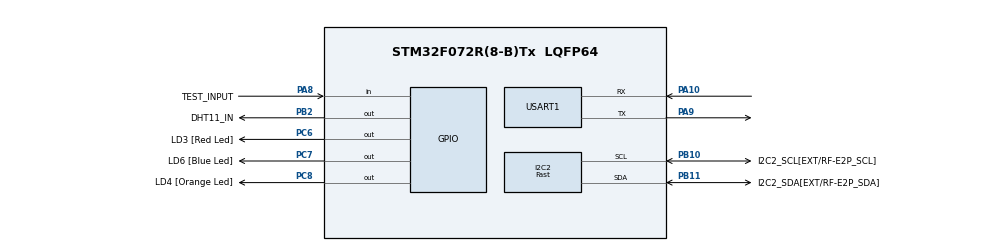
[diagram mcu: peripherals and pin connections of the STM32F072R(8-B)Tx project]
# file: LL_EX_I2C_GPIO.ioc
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I2C2.I2C_Speed_Mode=I2C_Fast
I2C2.Timing=0x2010091A
Mcu.Family=STM32F0
Mcu.Name=STM32F072R(8-B)Tx
Mcu.Package=LQFP64
NVIC.USART1_IRQn=true\:0\:0\:false\:false\:true\:true\:true
PA10.Mode=Asynchronous
PA10.Signal=USART1_RX
PA13.GPIO_Label=SWDIO
PA13.Mode=Serial_Wire
PA13.Signal=SYS_SWDIO
PA14.GPIO_Label=SWCLK
PA14.Mode=Serial_Wire
PA14.Signal=SYS_SWCLK
PA8.GPIO_Label=TEST_INPUT
PA8.Signal=GPIO_Input
PA9.Mode=Asynchronous
PA9.Signal=USART1_TX
PB10.GPIO_Label=I2C2_SCL[EXT/RF-E2P_SCL]
PB10.GPIO_Pu=GPIO_PULLUP
PB10.Mode=I2C
PB10.Signal=I2C2_SCL
PB11.GPIO_Label=I2C2_SDA[EXT/RF-E2P_SDA]
PB11.GPIO_Pu=GPIO_PULLUP
PB11.Mode=I2C
PB11.Signal=I2C2_SDA
PB2.GPIO_Label=DHT11_IN
PB2.GPIO_PuPd=GPIO_PULLUP
PB2.GPIO_Speed=GPIO_SPEED_FREQ_LOW
PB2.Signal=GPIO_Output
PC6.GPIO_Label=LD3 [Red Led]
PC6.Signal=GPIO_Output
PC7.GPIO_Label=LD6 [Blue Led]
PC7.Signal=GPIO_Output
PC8.GPIO_Label=LD4 [Orange Led]
PC8.Signal=GPIO_Output
ProjectManager.HeapSize=0x200
ProjectManager.StackSize=0x400
ProjectManager.TargetToolchain=STM32CubeIDE
RCC.AHBFreq_Value=48000000
RCC.APB1Freq_Value=48000000
RCC.APB1TimFreq_Value=48000000
RCC.HCLKFreq_Value=48000000
RCC.PLLMUL=RCC_PLL_MUL6
RCC.SYSCLKFreq_VALUE=48000000
RCC.SYSCLKSource=RCC_SYSCLKSOURCE_PLLCLK
TIM6.Prescaler=47
USART1.VirtualMode-Asynchronous=VM_ASYNC
VP_TIM6_VS_ClockSourceINT.Mode=Enable_Timer
board=STM32F072B-DISCO

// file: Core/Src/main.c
/* USER CODE BEGIN Header */
/**
  ******************************************************************************
  * @file           : main.c
  * @brief          : Main program body
  ******************************************************************************
  * @attention
  *
  * <h2><center>&copy; Copyright (c) 2021 STMicroelectronics.
  * All rights reserved.</center></h2>
  *
  * This software component is licensed by ST under BSD 3-Clause license,
  * the "License"; You may not use this file except in compliance with the
  * License. You may obtain a copy of the License at:
  *                        opensource.org/licenses/BSD-3-Clause
  *
  ******************************************************************************
  */
/* USER CODE END Header */
#include "main.h"

/* USER CODE BEGIN Includes */
#include "BSL.h"
/* USER CODE END Includes */

void SystemClock_Config(void);
static void MX_GPIO_Init(void);
static void MX_TIM6_Init(void);
static void MX_USART1_UART_Init(void);

int main(void)
{

  /* MCU Configuration--------------------------------------------------------*/

  /* Reset of all peripherals, Initializes the Flash interface and the Systick. */

  LL_APB1_GRP2_EnableClock(LL_APB1_GRP2_PERIPH_SYSCFG);
  LL_APB1_GRP1_EnableClock(LL_APB1_GRP1_PERIPH_PWR);

  /* System interrupt init*/

  /* Configure the system clock */
  SystemClock_Config();

  /* Initialize all configured peripherals */
  MX_GPIO_Init();
  MX_I2C2_Init();
  MX_TIM6_Init();
  MX_USART1_UART_Init();
  /* USER CODE BEGIN 2 */
  BSL_Startup();

  BSL_Config();

  BSL_Control();
  /* USER CODE END 2 */

  /* Infinite loop */
  while (1)
  {

  }
}

void SystemClock_Config(void)
{
  LL_FLASH_SetLatency(LL_FLASH_LATENCY_1);
  while(LL_FLASH_GetLatency() != LL_FLASH_LATENCY_1)
  {
  }
  LL_RCC_HSI_Enable();

   /* Wait till HSI is ready */
  while(LL_RCC_HSI_IsReady() != 1)
  {

  }
  LL_RCC_HSI_SetCalibTrimming(16);
  LL_RCC_PLL_ConfigDomain_SYS(LL_RCC_PLLSOURCE_HSI, LL_RCC_PLL_MUL_6, LL_RCC_PREDIV_DIV_1);
  LL_RCC_PLL_Enable();

   /* Wait till PLL is ready */
  while(LL_RCC_PLL_IsReady() != 1)
  {

  }
  LL_RCC_SetAHBPrescaler(LL_RCC_SYSCLK_DIV_1);
  LL_RCC_SetAPB1Prescaler(LL_RCC_APB1_DIV_1);
  LL_RCC_SetSysClkSource(LL_RCC_SYS_CLKSOURCE_PLL);

   /* Wait till System clock is ready */
  while(LL_RCC_GetSysClkSource() != LL_RCC_SYS_CLKSOURCE_STATUS_PLL)
  {

  }
  LL_Init1msTick(48000000);
  LL_SetSystemCoreClock(48000000);
  LL_RCC_SetUSARTClockSource(LL_RCC_USART1_CLKSOURCE_PCLK1);
}

void MX_I2C2_Init(void)
{

  LL_I2C_InitTypeDef I2C_InitStruct = {0};

  LL_GPIO_InitTypeDef GPIO_InitStruct = {0};

  LL_AHB1_GRP1_EnableClock(LL_AHB1_GRP1_PERIPH_GPIOB);
  /**I2C2 GPIO Configuration
  PB10   ------> I2C2_SCL
  PB11   ------> I2C2_SDA
  */
  GPIO_InitStruct.Pin = I2C2_SCL_Pin;
  GPIO_InitStruct.Mode = LL_GPIO_MODE_ALTERNATE;
  GPIO_InitStruct.Speed = LL_GPIO_SPEED_FREQ_HIGH;
  GPIO_InitStruct.OutputType = LL_GPIO_OUTPUT_OPENDRAIN;
  GPIO_InitStruct.Pull = LL_GPIO_PULL_UP;
  GPIO_InitStruct.Alternate = LL_GPIO_AF_1;
  LL_GPIO_Init(I2C2_SCL_GPIO_Port, &GPIO_InitStruct);

  GPIO_InitStruct.Pin = I2C2_SDA_Pin;
  GPIO_InitStruct.Mode = LL_GPIO_MODE_ALTERNATE;
  GPIO_InitStruct.Speed = LL_GPIO_SPEED_FREQ_HIGH;
  GPIO_InitStruct.OutputType = LL_GPIO_OUTPUT_OPENDRAIN;
  GPIO_InitStruct.Pull = LL_GPIO_PULL_UP;
  GPIO_InitStruct.Alternate = LL_GPIO_AF_1;
  LL_GPIO_Init(I2C2_SDA_GPIO_Port, &GPIO_InitStruct);

  /* Peripheral clock enable */
  LL_APB1_GRP1_EnableClock(LL_APB1_GRP1_PERIPH_I2C2);

  /** I2C Initialization
  */
  LL_I2C_DisableOwnAddress2(I2C2);
  LL_I2C_DisableGeneralCall(I2C2);
  LL_I2C_EnableClockStretching(I2C2);
  I2C_InitStruct.PeripheralMode = LL_I2C_MODE_I2C;
  I2C_InitStruct.Timing = 0x2010091A;
  I2C_InitStruct.AnalogFilter = LL_I2C_ANALOGFILTER_ENABLE;
  I2C_InitStruct.DigitalFilter = 0;
  I2C_InitStruct.OwnAddress1 = 0;
  I2C_InitStruct.TypeAcknowledge = LL_I2C_ACK;
  I2C_InitStruct.OwnAddrSize = LL_I2C_OWNADDRESS1_7BIT;
  LL_I2C_Init(I2C2, &I2C_InitStruct);
  LL_I2C_EnableAutoEndMode(I2C2);
  LL_I2C_SetOwnAddress2(I2C2, 0, LL_I2C_OWNADDRESS2_NOMASK);

}

static void MX_TIM6_Init(void)
{

  LL_TIM_InitTypeDef TIM_InitStruct = {0};

  /* Peripheral clock enable */
  LL_APB1_GRP1_EnableClock(LL_APB1_GRP1_PERIPH_TIM6);

  TIM_InitStruct.Prescaler = 47;
  TIM_InitStruct.CounterMode = LL_TIM_COUNTERMODE_UP;
  TIM_InitStruct.Autoreload = 65535;
  LL_TIM_Init(TIM6, &TIM_InitStruct);
  LL_TIM_DisableARRPreload(TIM6);
  LL_TIM_SetTriggerOutput(TIM6, LL_TIM_TRGO_RESET);
  LL_TIM_DisableMasterSlaveMode(TIM6);

}

static void MX_USART1_UART_Init(void)
{

  LL_USART_InitTypeDef USART_InitStruct = {0};

  LL_GPIO_InitTypeDef GPIO_InitStruct = {0};

  /* Peripheral clock enable */
  LL_APB1_GRP2_EnableClock(LL_APB1_GRP2_PERIPH_USART1);

  LL_AHB1_GRP1_EnableClock(LL_AHB1_GRP1_PERIPH_GPIOA);
  /**USART1 GPIO Configuration
  PA9   ------> USART1_TX
  PA10   ------> USART1_RX
  */
  GPIO_InitStruct.Pin = LL_GPIO_PIN_9;
  GPIO_InitStruct.Mode = LL_GPIO_MODE_ALTERNATE;
  GPIO_InitStruct.Speed = LL_GPIO_SPEED_FREQ_HIGH;
  GPIO_InitStruct.OutputType = LL_GPIO_OUTPUT_PUSHPULL;
  GPIO_InitStruct.Pull = LL_GPIO_PULL_NO;
  GPIO_InitStruct.Alternate = LL_GPIO_AF_1;
  LL_GPIO_Init(GPIOA, &GPIO_InitStruct);

  GPIO_InitStruct.Pin = LL_GPIO_PIN_10;
  GPIO_InitStruct.Mode = LL_GPIO_MODE_ALTERNATE;
  GPIO_InitStruct.Speed = LL_GPIO_SPEED_FREQ_HIGH;
  GPIO_InitStruct.OutputType = LL_GPIO_OUTPUT_PUSHPULL;
  GPIO_InitStruct.Pull = LL_GPIO_PULL_NO;
  GPIO_InitStruct.Alternate = LL_GPIO_AF_1;
  LL_GPIO_Init(GPIOA, &GPIO_InitStruct);

  /* USART1 interrupt Init */
  NVIC_SetPriority(USART1_IRQn, 0);
  NVIC_EnableIRQ(USART1_IRQn);

  USART_InitStruct.BaudRate = 38400;
  USART_InitStruct.DataWidth = LL_USART_DATAWIDTH_8B;
  USART_InitStruct.StopBits = LL_USART_STOPBITS_1;
  USART_InitStruct.Parity = LL_USART_PARITY_NONE;
  USART_InitStruct.TransferDirection = LL_USART_DIRECTION_TX_RX;
  USART_InitStruct.HardwareFlowControl = LL_USART_HWCONTROL_NONE;
  USART_InitStruct.OverSampling = LL_USART_OVERSAMPLING_16;
  LL_USART_Init(USART1, &USART_InitStruct);
  LL_USART_DisableIT_CTS(USART1);
  LL_USART_ConfigAsyncMode(USART1);
  LL_USART_Enable(USART1);

}

static void MX_GPIO_Init(void)
{
  LL_GPIO_InitTypeDef GPIO_InitStruct = {0};

  /* GPIO Ports Clock Enable */
  LL_AHB1_GRP1_EnableClock(LL_AHB1_GRP1_PERIPH_GPIOB);
  LL_AHB1_GRP1_EnableClock(LL_AHB1_GRP1_PERIPH_GPIOC);
  LL_AHB1_GRP1_EnableClock(LL_AHB1_GRP1_PERIPH_GPIOA);

  /**/
  LL_GPIO_ResetOutputPin(DHT11_IN_GPIO_Port, DHT11_IN_Pin);

  /**/
  LL_GPIO_ResetOutputPin(LD3_GPIO_Port, LD3_Pin);

  /**/
  LL_GPIO_ResetOutputPin(LD6_GPIO_Port, LD6_Pin);

  /**/
  LL_GPIO_ResetOutputPin(LD4_GPIO_Port, LD4_Pin);

  /**/
  GPIO_InitStruct.Pin = DHT11_IN_Pin;
  GPIO_InitStruct.Mode = LL_GPIO_MODE_OUTPUT;
  GPIO_InitStruct.Speed = LL_GPIO_SPEED_FREQ_LOW;
  GPIO_InitStruct.OutputType = LL_GPIO_OUTPUT_PUSHPULL;
  GPIO_InitStruct.Pull = LL_GPIO_PULL_UP;
  LL_GPIO_Init(DHT11_IN_GPIO_Port, &GPIO_InitStruct);

  /**/
  GPIO_InitStruct.Pin = LD3_Pin;
  GPIO_InitStruct.Mode = LL_GPIO_MODE_OUTPUT;
  GPIO_InitStruct.Speed = LL_GPIO_SPEED_FREQ_LOW;
  GPIO_InitStruct.OutputType = LL_GPIO_OUTPUT_PUSHPULL;
  GPIO_InitStruct.Pull = LL_GPIO_PULL_NO;
  LL_GPIO_Init(LD3_GPIO_Port, &GPIO_InitStruct);

  /**/
  GPIO_InitStruct.Pin = LD6_Pin;
  GPIO_InitStruct.Mode = LL_GPIO_MODE_OUTPUT;
  GPIO_InitStruct.Speed = LL_GPIO_SPEED_FREQ_LOW;
  GPIO_InitStruct.OutputType = LL_GPIO_OUTPUT_PUSHPULL;
  GPIO_InitStruct.Pull = LL_GPIO_PULL_NO;
  LL_GPIO_Init(LD6_GPIO_Port, &GPIO_InitStruct);

  /**/
  GPIO_InitStruct.Pin = LD4_Pin;
  GPIO_InitStruct.Mode = LL_GPIO_MODE_OUTPUT;
  GPIO_InitStruct.Speed = LL_GPIO_SPEED_FREQ_LOW;
  GPIO_InitStruct.OutputType = LL_GPIO_OUTPUT_PUSHPULL;
  GPIO_InitStruct.Pull = LL_GPIO_PULL_NO;
  LL_GPIO_Init(LD4_GPIO_Port, &GPIO_InitStruct);

  /**/
  GPIO_InitStruct.Pin = TEST_INPUT_Pin;
  GPIO_InitStruct.Mode = LL_GPIO_MODE_INPUT;
  GPIO_InitStruct.Pull = LL_GPIO_PULL_NO;
  LL_GPIO_Init(TEST_INPUT_GPIO_Port, &GPIO_InitStruct);

}

void Error_Handler(void)
{
  __disable_irq();
  while (1)
  {
  }
}
